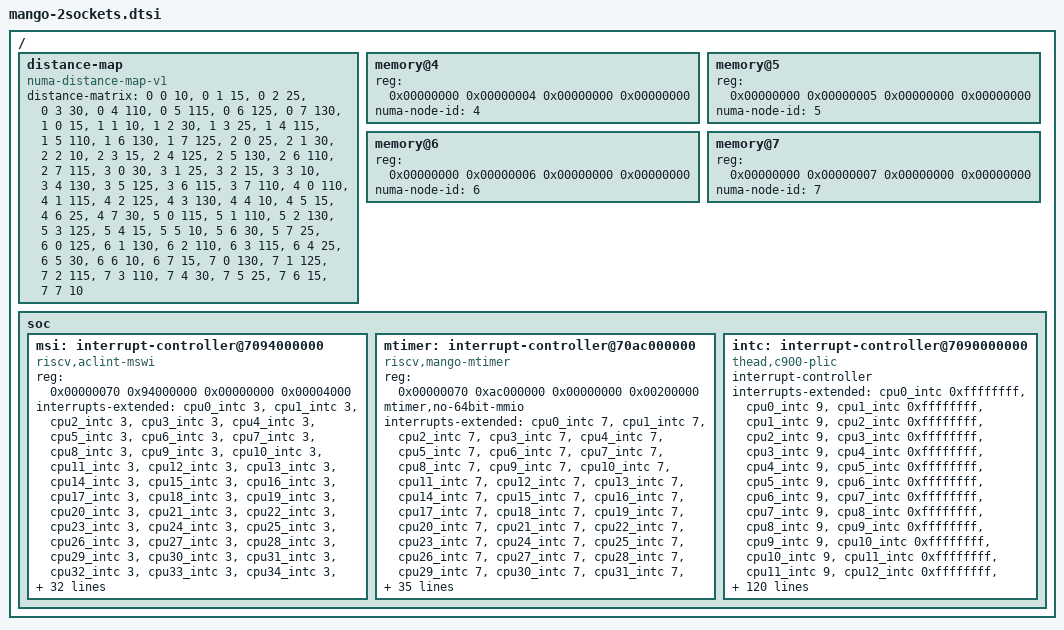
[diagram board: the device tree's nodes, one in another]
#include "mango.dtsi"
#include "mango-cpus-socket1.dtsi"

/ {
	/delete-node/ distance-map;
	distance-map {
		compatible = "numa-distance-map-v1";
		distance-matrix = <0 0 10>,	//chip0
				  <0 1 15>,
				  <0 2 25>,
				  <0 3 30>,
				  <0 4 110>,
				  <0 5 115>,
				  <0 6 125>,
				  <0 7 130>,
				  <1 0 15>,
				  <1 1 10>,
				  <1 2 30>,
				  <1 3 25>,
				  <1 4 115>,
				  <1 5 110>,
				  <1 6 130>,
				  <1 7 125>,
				  <2 0 25>,
				  <2 1 30>,
				  <2 2 10>,
				  <2 3 15>,
				  <2 4 125>,
				  <2 5 130>,
				  <2 6 110>,
				  <2 7 115>,
				  <3 0 30>,
				  <3 1 25>,
				  <3 2 15>,
				  <3 3 10>,
				  <3 4 130>,
				  <3 5 125>,
				  <3 6 115>,
				  <3 7 110>,
				  <4 0 110>,	//chip1
				  <4 1 115>,
				  <4 2 125>,
				  <4 3 130>,
				  <4 4 10>,
				  <4 5 15>,
				  <4 6 25>,
				  <4 7 30>,
				  <5 0 115>,
				  <5 1 110>,
				  <5 2 130>,
				  <5 3 125>,
				  <5 4 15>,
				  <5 5 10>,
				  <5 6 30>,
				  <5 7 25>,
				  <6 0 125>,
				  <6 1 130>,
				  <6 2 110>,
				  <6 3 115>,
				  <6 4 25>,
				  <6 5 30>,
				  <6 6 10>,
				  <6 7 15>,
				  <7 0 130>,
				  <7 1 125>,
				  <7 2 115>,
				  <7 3 110>,
				  <7 4 30>,
				  <7 5 25>,
				  <7 6 15>,
				  <7 7 10>;
	};

	/* the mem node will be updated by ZSBL. */
	/* chip 1 */
	memory@4 {
		device_type = "memory";
		reg = <0x00000000 0x00000004 0x00000000 0x00000000>;
		numa-node-id = <4>;
	};
	memory@5 {
		device_type = "memory";
		reg = <0x00000000 0x00000005 0x00000000 0x00000000>;
		numa-node-id = <5>;
	};
	memory@6 {
		device_type = "memory";
		reg = <0x00000000 0x00000006 0x00000000 0x00000000>;
		numa-node-id = <6>;
	};
	memory@7 {
		device_type = "memory";
		reg = <0x00000000 0x00000007 0x00000000 0x00000000>;
		numa-node-id = <7>;
	};

	soc {
		/delete-node/ interrupt-controller@7094000000;
		msi: interrupt-controller@7094000000 {
			compatible = "riscv,aclint-mswi";
			reg = <0x00000070 0x94000000 0x00000000 0x00004000>;
			interrupts-extended = <
				&cpu0_intc 3
				&cpu1_intc 3
				&cpu2_intc 3
				&cpu3_intc 3
				&cpu4_intc 3
				&cpu5_intc 3
				&cpu6_intc 3
				&cpu7_intc 3
				&cpu8_intc 3
				&cpu9_intc 3
				&cpu10_intc 3
				&cpu11_intc 3
				&cpu12_intc 3
				&cpu13_intc 3
				&cpu14_intc 3
				&cpu15_intc 3
				&cpu16_intc 3
				&cpu17_intc 3
				&cpu18_intc 3
				&cpu19_intc 3
				&cpu20_intc 3
				&cpu21_intc 3
				&cpu22_intc 3
				&cpu23_intc 3
				&cpu24_intc 3
				&cpu25_intc 3
				&cpu26_intc 3
				&cpu27_intc 3
				&cpu28_intc 3
				&cpu29_intc 3
				&cpu30_intc 3
				&cpu31_intc 3
				&cpu32_intc 3
				&cpu33_intc 3
				&cpu34_intc 3
				&cpu35_intc 3
				&cpu36_intc 3
				&cpu37_intc 3
				&cpu38_intc 3
				&cpu39_intc 3
				&cpu40_intc 3
				&cpu41_intc 3
				&cpu42_intc 3
				&cpu43_intc 3
				&cpu44_intc 3
				&cpu45_intc 3
				&cpu46_intc 3
				&cpu47_intc 3
				&cpu48_intc 3
				&cpu49_intc 3
				&cpu50_intc 3
				&cpu51_intc 3
				&cpu52_intc 3
				&cpu53_intc 3
				&cpu54_intc 3
				&cpu55_intc 3
				&cpu56_intc 3
				&cpu57_intc 3
				&cpu58_intc 3
				&cpu59_intc 3
				&cpu60_intc 3
				&cpu61_intc 3
				&cpu62_intc 3
				&cpu63_intc 3

				// chip 1
				&cpu64_intc 3
				&cpu65_intc 3
				&cpu66_intc 3
				&cpu67_intc 3
				&cpu68_intc 3
				&cpu69_intc 3
				&cpu70_intc 3
				&cpu71_intc 3
				&cpu72_intc 3
				&cpu73_intc 3
				&cpu74_intc 3
				&cpu75_intc 3
				&cpu76_intc 3
				&cpu77_intc 3
				&cpu78_intc 3
				&cpu79_intc 3
				&cpu80_intc 3
				&cpu81_intc 3
				&cpu82_intc 3
				&cpu83_intc 3
				&cpu84_intc 3
				&cpu85_intc 3
				&cpu86_intc 3
				&cpu87_intc 3
				&cpu88_intc 3
				&cpu89_intc 3
				&cpu90_intc 3
				&cpu91_intc 3
				&cpu92_intc 3
				&cpu93_intc 3
				&cpu94_intc 3
				&cpu95_intc 3
				&cpu96_intc 3
				&cpu97_intc 3
				&cpu98_intc 3
				&cpu99_intc 3
				&cpu100_intc 3
				&cpu101_intc 3
				&cpu102_intc 3
				&cpu103_intc 3
				&cpu104_intc 3
				&cpu105_intc 3
				&cpu106_intc 3
				&cpu107_intc 3
				&cpu108_intc 3
				&cpu109_intc 3
				&cpu110_intc 3
				&cpu111_intc 3
				&cpu112_intc 3
				&cpu113_intc 3
				&cpu114_intc 3
				&cpu115_intc 3
				&cpu116_intc 3
				&cpu117_intc 3
				&cpu118_intc 3
				&cpu119_intc 3
				&cpu120_intc 3
				&cpu121_intc 3
				&cpu122_intc 3
				&cpu123_intc 3
				&cpu124_intc 3
				&cpu125_intc 3
				&cpu126_intc 3
				&cpu127_intc 3
				>;
			interrupt-controller;
			#interrupt-cells = <0>;
		};

		/delete-node/ interrupt-controller@70ac000000;
		mtimer: interrupt-controller@70ac000000 {
			compatible = "riscv,mango-mtimer";
			reg = <0x00000070 0xac000000 0x00000000 0x00200000>;
			mtimer,no-64bit-mmio;
			interrupts-extended = <
				&cpu0_intc 7
				&cpu1_intc 7
				&cpu2_intc 7
				&cpu3_intc 7
				&cpu4_intc 7
				&cpu5_intc 7
				&cpu6_intc 7
				&cpu7_intc 7
				&cpu8_intc 7
				&cpu9_intc 7
				&cpu10_intc 7
				&cpu11_intc 7
				&cpu12_intc 7
				&cpu13_intc 7
				&cpu14_intc 7
				&cpu15_intc 7
				&cpu16_intc 7
				&cpu17_intc 7
				&cpu18_intc 7
				&cpu19_intc 7
				&cpu20_intc 7
				&cpu21_intc 7
				&cpu22_intc 7
				&cpu23_intc 7
				&cpu24_intc 7
				&cpu25_intc 7
				&cpu26_intc 7
				&cpu27_intc 7
				&cpu28_intc 7
				&cpu29_intc 7
				&cpu30_intc 7
				&cpu31_intc 7
				&cpu32_intc 7
				&cpu33_intc 7
				&cpu34_intc 7
				&cpu35_intc 7
				&cpu36_intc 7
				&cpu37_intc 7
				&cpu38_intc 7
				&cpu39_intc 7
				&cpu40_intc 7
				&cpu41_intc 7
				&cpu42_intc 7
				&cpu43_intc 7
				&cpu44_intc 7
				&cpu45_intc 7
				&cpu46_intc 7
				&cpu47_intc 7
				&cpu48_intc 7
				&cpu49_intc 7
				&cpu50_intc 7
				&cpu51_intc 7
				&cpu52_intc 7
				&cpu53_intc 7
				&cpu54_intc 7
				&cpu55_intc 7
				&cpu56_intc 7
				&cpu57_intc 7
				&cpu58_intc 7
				&cpu59_intc 7
				&cpu60_intc 7
				&cpu61_intc 7
				&cpu62_intc 7
				&cpu63_intc 7

				// chip 1
				&cpu64_intc 7
				&cpu65_intc 7
				&cpu66_intc 7
				&cpu67_intc 7
				&cpu68_intc 7
				&cpu69_intc 7
				&cpu70_intc 7
				&cpu71_intc 7
				&cpu72_intc 7
				&cpu73_intc 7
				&cpu74_intc 7
				&cpu75_intc 7
				&cpu76_intc 7
				&cpu77_intc 7
				&cpu78_intc 7
				&cpu79_intc 7
				&cpu80_intc 7
				&cpu81_intc 7
				&cpu82_intc 7
				&cpu83_intc 7
				&cpu84_intc 7
				&cpu85_intc 7
				&cpu86_intc 7
				&cpu87_intc 7
				&cpu88_intc 7
				&cpu89_intc 7
				&cpu90_intc 7
				&cpu91_intc 7
				&cpu92_intc 7
				&cpu93_intc 7
				&cpu94_intc 7
				&cpu95_intc 7
				&cpu96_intc 7
				&cpu97_intc 7
				&cpu98_intc 7
				&cpu99_intc 7
				&cpu100_intc 7
				&cpu101_intc 7
				&cpu102_intc 7
				&cpu103_intc 7
				&cpu104_intc 7
				&cpu105_intc 7
				&cpu106_intc 7
				&cpu107_intc 7
				&cpu108_intc 7
				&cpu109_intc 7
				&cpu110_intc 7
				&cpu111_intc 7
				&cpu112_intc 7
				&cpu113_intc 7
				&cpu114_intc 7
				&cpu115_intc 7
				&cpu116_intc 7
				&cpu117_intc 7
				&cpu118_intc 7
				&cpu119_intc 7
				&cpu120_intc 7
				&cpu121_intc 7
				&cpu122_intc 7
				&cpu123_intc 7
				&cpu124_intc 7
				&cpu125_intc 7
				&cpu126_intc 7
				&cpu127_intc 7
				>;
			interrupt-controller;
			#interrupt-cells = <0>;
			cores-per-cluster = <4>;
			cluster-mtimer-offset = <0x00010000>;
		};

		/delete-node/ interrupt-controller@7090000000;
		intc: interrupt-controller@7090000000 {
			#address-cells = <0>;
			#interrupt-cells = <2>;
			compatible = "thead,c900-plic","riscv,plic0";
			interrupt-controller;
			interrupts-extended = <
				&cpu0_intc  0xffffffff &cpu0_intc  9
				&cpu1_intc  0xffffffff &cpu1_intc  9
				&cpu2_intc  0xffffffff &cpu2_intc  9
				&cpu3_intc  0xffffffff &cpu3_intc  9
				&cpu4_intc  0xffffffff &cpu4_intc  9
				&cpu5_intc  0xffffffff &cpu5_intc  9
				&cpu6_intc  0xffffffff &cpu6_intc  9
				&cpu7_intc  0xffffffff &cpu7_intc  9
				&cpu8_intc  0xffffffff &cpu8_intc  9
				&cpu9_intc  0xffffffff &cpu9_intc  9
				&cpu10_intc  0xffffffff &cpu10_intc  9
				&cpu11_intc  0xffffffff &cpu11_intc  9
				&cpu12_intc  0xffffffff &cpu12_intc  9
				&cpu13_intc  0xffffffff &cpu13_intc  9
				&cpu14_intc  0xffffffff &cpu14_intc  9
				&cpu15_intc  0xffffffff &cpu15_intc  9
				&cpu16_intc  0xffffffff &cpu16_intc  9
				&cpu17_intc  0xffffffff &cpu17_intc  9
				&cpu18_intc  0xffffffff &cpu18_intc  9
				&cpu19_intc  0xffffffff &cpu19_intc  9
				&cpu20_intc  0xffffffff &cpu20_intc  9
				&cpu21_intc  0xffffffff &cpu21_intc  9
				&cpu22_intc  0xffffffff &cpu22_intc  9
				&cpu23_intc  0xffffffff &cpu23_intc  9
				&cpu24_intc  0xffffffff &cpu24_intc  9
				&cpu25_intc  0xffffffff &cpu25_intc  9
				&cpu26_intc  0xffffffff &cpu26_intc  9
				&cpu27_intc  0xffffffff &cpu27_intc  9
				&cpu28_intc  0xffffffff &cpu28_intc  9
				&cpu29_intc  0xffffffff &cpu29_intc  9
				&cpu30_intc  0xffffffff &cpu30_intc  9
				&cpu31_intc  0xffffffff &cpu31_intc  9
				&cpu32_intc  0xffffffff &cpu32_intc  9
				&cpu33_intc  0xffffffff &cpu33_intc  9
				&cpu34_intc  0xffffffff &cpu34_intc  9
				&cpu35_intc  0xffffffff &cpu35_intc  9
				&cpu36_intc  0xffffffff &cpu36_intc  9
				&cpu37_intc  0xffffffff &cpu37_intc  9
				&cpu38_intc  0xffffffff &cpu38_intc  9
				&cpu39_intc  0xffffffff &cpu39_intc  9
				&cpu40_intc  0xffffffff &cpu40_intc  9
				&cpu41_intc  0xffffffff &cpu41_intc  9
				&cpu42_intc  0xffffffff &cpu42_intc  9
				&cpu43_intc  0xffffffff &cpu43_intc  9
				&cpu44_intc  0xffffffff &cpu44_intc  9
				&cpu45_intc  0xffffffff &cpu45_intc  9
				&cpu46_intc  0xffffffff &cpu46_intc  9
				&cpu47_intc  0xffffffff &cpu47_intc  9
				&cpu48_intc  0xffffffff &cpu48_intc  9
				&cpu49_intc  0xffffffff &cpu49_intc  9
				&cpu50_intc  0xffffffff &cpu50_intc  9
				&cpu51_intc  0xffffffff &cpu51_intc  9
				&cpu52_intc  0xffffffff &cpu52_intc  9
				&cpu53_intc  0xffffffff &cpu53_intc  9
				&cpu54_intc  0xffffffff &cpu54_intc  9
				&cpu55_intc  0xffffffff &cpu55_intc  9
				&cpu56_intc  0xffffffff &cpu56_intc  9
				&cpu57_intc  0xffffffff &cpu57_intc  9
				&cpu58_intc  0xffffffff &cpu58_intc  9
				&cpu59_intc  0xffffffff &cpu59_intc  9
				&cpu60_intc  0xffffffff &cpu60_intc  9
				&cpu61_intc  0xffffffff &cpu61_intc  9
				&cpu62_intc  0xffffffff &cpu62_intc  9
				&cpu63_intc  0xffffffff &cpu63_intc  9

				//chip 1
				&cpu64_intc  0xffffffff &cpu64_intc  9
				&cpu65_intc  0xffffffff &cpu65_intc  9
				&cpu66_intc  0xffffffff &cpu66_intc  9
				&cpu67_intc  0xffffffff &cpu67_intc  9
				&cpu68_intc  0xffffffff &cpu68_intc  9
				&cpu69_intc  0xffffffff &cpu69_intc  9
				&cpu70_intc  0xffffffff &cpu70_intc  9
				&cpu71_intc  0xffffffff &cpu71_intc  9
				&cpu72_intc  0xffffffff &cpu72_intc  9
				&cpu73_intc  0xffffffff &cpu73_intc  9
				&cpu74_intc  0xffffffff &cpu74_intc  9
				&cpu75_intc  0xffffffff &cpu75_intc  9
				&cpu76_intc  0xffffffff &cpu76_intc  9
				&cpu77_intc  0xffffffff &cpu77_intc  9
				&cpu78_intc  0xffffffff &cpu78_intc  9
				&cpu79_intc  0xffffffff &cpu79_intc  9
				&cpu80_intc  0xffffffff &cpu80_intc  9
				&cpu81_intc  0xffffffff &cpu81_intc  9
				&cpu82_intc  0xffffffff &cpu82_intc  9
				&cpu83_intc  0xffffffff &cpu83_intc  9
				&cpu84_intc  0xffffffff &cpu84_intc  9
				&cpu85_intc  0xffffffff &cpu85_intc  9
				&cpu86_intc  0xffffffff &cpu86_intc  9
				&cpu87_intc  0xffffffff &cpu87_intc  9
				&cpu88_intc  0xffffffff &cpu88_intc  9
				&cpu89_intc  0xffffffff &cpu89_intc  9
				&cpu90_intc  0xffffffff &cpu90_intc  9
				&cpu91_intc  0xffffffff &cpu91_intc  9
				&cpu92_intc  0xffffffff &cpu92_intc  9
				&cpu93_intc  0xffffffff &cpu93_intc  9
				&cpu94_intc  0xffffffff &cpu94_intc  9
				&cpu95_intc  0xffffffff &cpu95_intc  9
				&cpu96_intc  0xffffffff &cpu96_intc  9
				&cpu97_intc  0xffffffff &cpu97_intc  9
				&cpu98_intc  0xffffffff &cpu98_intc  9
				&cpu99_intc  0xffffffff &cpu99_intc  9
				&cpu100_intc  0xffffffff &cpu100_intc  9
				&cpu101_intc  0xffffffff &cpu101_intc  9
				&cpu102_intc  0xffffffff &cpu102_intc  9
				&cpu103_intc  0xffffffff &cpu103_intc  9
				&cpu104_intc  0xffffffff &cpu104_intc  9
				&cpu105_intc  0xffffffff &cpu105_intc  9
				&cpu106_intc  0xffffffff &cpu106_intc  9
				&cpu107_intc  0xffffffff &cpu107_intc  9
				&cpu108_intc  0xffffffff &cpu108_intc  9
				&cpu109_intc  0xffffffff &cpu109_intc  9
				&cpu110_intc  0xffffffff &cpu110_intc  9
				&cpu111_intc  0xffffffff &cpu111_intc  9
				&cpu112_intc  0xffffffff &cpu112_intc  9
				&cpu113_intc  0xffffffff &cpu113_intc  9
				&cpu114_intc  0xffffffff &cpu114_intc  9
				&cpu115_intc  0xffffffff &cpu115_intc  9
				&cpu116_intc  0xffffffff &cpu116_intc  9
				&cpu117_intc  0xffffffff &cpu117_intc  9
				&cpu118_intc  0xffffffff &cpu118_intc  9
				&cpu119_intc  0xffffffff &cpu119_intc  9
				&cpu120_intc  0xffffffff &cpu120_intc  9
				&cpu121_intc  0xffffffff &cpu121_intc  9
				&cpu122_intc  0xffffffff &cpu122_intc  9
				&cpu123_intc  0xffffffff &cpu123_intc  9
				&cpu124_intc  0xffffffff &cpu124_intc  9
				&cpu125_intc  0xffffffff &cpu125_intc  9
				&cpu126_intc  0xffffffff &cpu126_intc  9
				&cpu127_intc  0xffffffff &cpu127_intc  9
				>;
			reg = <0x00000070 0x90000000 0x00000000 0x04000000>;
			reg-names = "control";
			riscv,max-priority = <7>;
			riscv,ndev = <172>;
		};
	};
};
